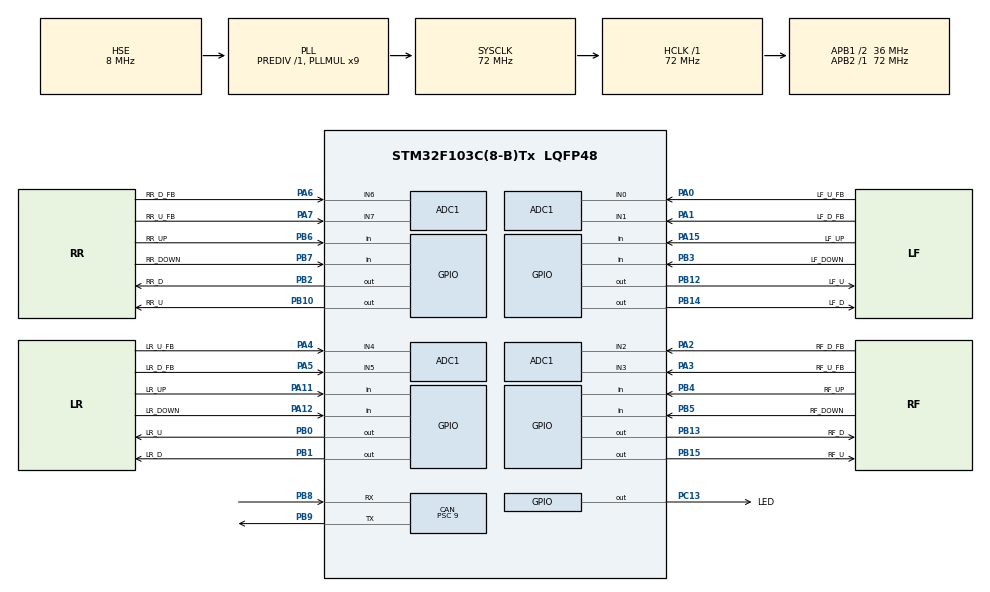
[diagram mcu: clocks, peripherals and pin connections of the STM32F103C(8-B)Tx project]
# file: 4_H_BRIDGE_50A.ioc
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Mcu.Family=STM32F1
PB10.GPIO_PuPd=GPIO_PULLDOWN
ADC1.ContinuousConvMode=ENABLE
SH.ADCx_IN2.0=ADC1_IN2,IN2
PB14.GPIO_Label=LF_D
PA6.GPIO_Label=RR_D_FB
PB0.GPIO_Label=LR_U
PB6.GPIO_Label=RR_UP
PA11.GPIO_PuPd=GPIO_PULLUP
PB13.GPIO_Label=RF_D
PB13.Signal=GPIO_Output
PB15.Signal=GPIO_Output
RCC.SYSCLKSource=RCC_SYSCLKSOURCE_PLLCLK
ProjectManager.StackSize=0x400
PD1-OSC_OUT.Signal=RCC_OSC_OUT
PA15.GPIO_Label=LF_UP
PA12.Signal=GPIO_Input
CAN.Prescaler=9
ADC1.Channel-3\#ChannelRegularConversion=ADC_CHANNEL_3
PB1.GPIO_PuPd=GPIO_PULLDOWN
RCC.HCLKFreq_Value=72000000
SH.ADCx_IN3.0=ADC1_IN3,IN3
RCC.APB2TimFreq_Value=72000000
PB6.Signal=GPIO_Input
Dma.ADC1.0.Direction=DMA_PERIPH_TO_MEMORY
ADC1.Channel-2\#ChannelRegularConversion=ADC_CHANNEL_2
Dma.ADC1.0.MemDataAlignment=DMA_MDATAALIGN_WORD
RCC.AHBFreq_Value=72000000
VP_TIM4_VS_ControllerModeTrigger.Mode=Trigger Mode
ADC1.Channel-0\#ChannelRegularConversion=ADC_CHANNEL_0
PB2.Signal=GPIO_Output
RCC.PLLMUL=RCC_PLL_MUL9
PB12.GPIO_Label=LF_U
PB3.GPIO_PuPd=GPIO_PULLUP
ADC1.Rank-2\#ChannelRegularConversion=3
PC14-OSC32_IN.Mode=LSE-External-Oscillator
PA14.Mode=Serial_Wire
PB1.GPIO_Label=LR_D
Dma.ADC1.0.PeriphInc=DMA_PINC_DISABLE
PB7.Signal=GPIO_Input
SH.ADCx_IN0.0=ADC1_IN0,IN0
TIM4.Period=200
CAN.CalculateTimeQuantum=250.0
PB2.GPIO_PuPd=GPIO_PULLDOWN
ADC1.SamplingTime-0\#ChannelRegularConversion=ADC_SAMPLETIME_1CYCLE_5
PB7.GPIO_Label=RR_DOWN
Mcu.Package=LQFP48
PB9.Signal=CAN_TX
PB14.GPIO_PuPd=GPIO_PULLDOWN
PB1.Signal=GPIO_Output
PA6.Signal=ADCx_IN6
ADC1.EnableInjectedConversion=DISABLE
PB15.GPIO_PuPd=GPIO_PULLDOWN
PA2.GPIO_Label=RF_D_FB
PA15.Signal=GPIO_Input
SH.ADCx_IN1.0=ADC1_IN1,IN1
PB5.GPIO_Label=RF_DOWN
RCC.APB1TimFreq_Value=72000000
PA12.GPIO_PuPd=GPIO_PULLUP
Dma.Request0=ADC1
PA4.GPIO_Label=LR_U_FB
PB4.Signal=GPIO_Input
PA3.Signal=ADCx_IN3
PB3.GPIO_Label=LF_DOWN
PB7.GPIO_PuPd=GPIO_PULLUP
RCC.PLLSourceVirtual=RCC_PLLSOURCE_HSE
PC15-OSC32_OUT.Mode=LSE-External-Oscillator
Dma.ADC1.0.Instance=DMA1_Channel1
ADC1.Rank-0\#ChannelRegularConversion=1
PD1-OSC_OUT.Mode=HSE-External-Oscillator
SH.ADCx_IN6.0=ADC1_IN6,IN6
CAN.CalculateBaudRate=500000
PB6.GPIO_PuPd=GPIO_PULLUP
PC13-TAMPER-RTC.Signal=GPIO_Output
PA11.GPIO_Label=LR_UP
PD0-OSC_IN.Signal=RCC_OSC_IN
RCC.APB1CLKDivider=RCC_HCLK_DIV2
PC14-OSC32_IN.Signal=RCC_OSC32_IN
CAN.CalculateTimeBit=2000.00
PA12.GPIO_Label=LR_DOWN
ADC1.SamplingTime-2\#ChannelRegularConversion=ADC_SAMPLETIME_13CYCLES_5
PA0-WKUP.GPIO_Label=LF_U_FB
PA0-WKUP.Signal=ADCx_IN0
RCC.ADCPresc=RCC_ADCPCLK2_DIV6
PA13.Signal=SYS_JTMS-SWDIO
Dma.ADC1.0.PeriphDataAlignment=DMA_PDATAALIGN_WORD
CAN.BS2=CAN_BS2_3TQ
CAN.BS1=CAN_BS1_4TQ
ProjectManager.TargetToolchain=Makefile
PB10.GPIO_Label=RR_U
SH.ADCx_IN7.0=ADC1_IN7,IN7
Dma.ADC1.0.Mode=DMA_CIRCULAR
PB9.Mode=CAN_Activate
Dma.ADC1.0.Priority=DMA_PRIORITY_MEDIUM
ADC1.Channel-1\#ChannelRegularConversion=ADC_CHANNEL_1
PB4.GPIO_PuPd=GPIO_PULLUP
RCC.USBFreq_Value=72000000
PC15-OSC32_OUT.Signal=RCC_OSC32_OUT
PA1.Signal=ADCx_IN1
PD0-OSC_IN.Mode=HSE-External-Oscillator
PB10.Signal=GPIO_Output
PB14.Signal=GPIO_Output
PA5.Signal=ADCx_IN5
board=custom
PC13-TAMPER-RTC.GPIO_Label=LED
PB13.GPIO_PuPd=GPIO_PULLDOWN
RCC.APB2Freq_Value=72000000
PB4.GPIO_Label=RF_UP
PB15.GPIO_Label=RF_U
VP_TIM4_VS_ClockSourceITR.Mode=TriggerSource_ITR0
NVIC.USB_LP_CAN1_RX0_IRQn=true\:0\:0\:false\:false\:true\:true\:true
PA1.GPIO_Label=LF_D_FB
SH.ADCx_IN4.0=ADC1_IN4,IN4
ADC1.NbrOfConversion=4
PA13.Mode=Serial_Wire
Mcu.Name=STM32F103C(8-B)Tx
PA2.Signal=ADCx_IN2
PB3.Signal=GPIO_Input
PA4.Signal=ADCx_IN4
ADC1.SamplingTime-1\#ChannelRegularConversion=ADC_SAMPLETIME_13CYCLES_5
RCC.SYSCLKFreq_VALUE=72000000
PB5.Signal=GPIO_Input
PA7.GPIO_Label=RR_U_FB
ADC1.master=1
PA5.GPIO_Label=LR_D_FB
ADC1.Rank-3\#ChannelRegularConversion=4
ADC1.SamplingTime-3\#ChannelRegularConversion=ADC_SAMPLETIME_13CYCLES_5
PB5.GPIO_PuPd=GPIO_PULLUP
ADC1.Rank-1\#ChannelRegularConversion=2
PA11.Signal=GPIO_Input
PA14.Signal=SYS_JTCK-SWCLK
Dma.ADC1.0.MemInc=DMA_MINC_ENABLE
PB2.GPIO_Label=RR_D
ProjectManager.HeapSize=0x200
SH.ADCx_IN5.0=ADC1_IN5,IN5
NVIC.PriorityGroup=NVIC_PRIORITYGROUP_4
ADC1.NbrOfConversionFlag=1
PB8.Mode=CAN_Activate
PA15.GPIO_PuPd=GPIO_PULLUP
PB8.Signal=CAN_RX
NVIC.DMA1_Channel1_IRQn=true\:0\:0\:false\:false\:true\:false\:true
PB12.GPIO_PuPd=GPIO_PULLDOWN
NVIC.TIM4_IRQn=true\:0\:0\:false\:false\:true\:true\:true
RCC.APB1Freq_Value=36000000
PB0.Signal=GPIO_Output
PB12.Signal=GPIO_Output
PB0.GPIO_PuPd=GPIO_PULLDOWN
PA3.GPIO_Label=RF_U_FB
PA7.Signal=ADCx_IN7

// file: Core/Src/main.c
/* USER CODE BEGIN Header */
/**
  ******************************************************************************
  * @file           : main.c
  * @brief          : Main program body
  ******************************************************************************
  * @attention
  *
  * <h2><center>&copy; Copyright (c) 2021 STMicroelectronics.
  * All rights reserved.</center></h2>
  *
  * This software component is licensed by ST under BSD 3-Clause license,
  * the "License"; You may not use this file except in compliance with the
  * License. You may obtain a copy of the License at:
  *                        opensource.org/licenses/BSD-3-Clause
  *
  ******************************************************************************
  */
/* USER CODE END Header */
#include "main.h"

/* USER CODE BEGIN Includes */
#include "window.h"
#include "can_setup.h"
/* USER CODE END Includes */

ADC_HandleTypeDef hadc1;
DMA_HandleTypeDef hdma_adc1;

CAN_HandleTypeDef hcan;

TIM_HandleTypeDef htim4;

void SystemClock_Config(void);
static void MX_GPIO_Init(void);
static void MX_DMA_Init(void);
static void MX_ADC1_Init(void);
static void MX_CAN_Init(void);
static void MX_TIM4_Init(void);

int main(void)
{

  /* MCU Configuration--------------------------------------------------------*/

  /* Reset of all peripherals, Initializes the Flash interface and the Systick. */
  HAL_Init();

  /* Configure the system clock */
  SystemClock_Config();

  /* Initialize all configured peripherals */
  MX_GPIO_Init();
  MX_DMA_Init();
  MX_ADC1_Init();
  MX_CAN_Init();
  MX_TIM4_Init();
  /* USER CODE BEGIN 2 */
  canSettings();
  windowInit();
  HAL_ADC_Start_DMA(&hadc1, motorCurrent, 8); // start adc in DMA mode
  /* USER CODE END 2 */

  /* Infinite loop */
  /* USER CODE BEGIN WHILE */
  while (1)
  {
    windowHandler();

    /* USER CODE END WHILE */

  }
}

void SystemClock_Config(void)
{
  RCC_OscInitTypeDef RCC_OscInitStruct = {0};
  RCC_ClkInitTypeDef RCC_ClkInitStruct = {0};
  RCC_PeriphCLKInitTypeDef PeriphClkInit = {0};

  /** Initializes the RCC Oscillators according to the specified parameters
  * in the RCC_OscInitTypeDef structure.
  */
  RCC_OscInitStruct.OscillatorType = RCC_OSCILLATORTYPE_HSE;
  RCC_OscInitStruct.HSEState = RCC_HSE_ON;
  RCC_OscInitStruct.HSEPredivValue = RCC_HSE_PREDIV_DIV1;
  RCC_OscInitStruct.HSIState = RCC_HSI_ON;
  RCC_OscInitStruct.PLL.PLLState = RCC_PLL_ON;
  RCC_OscInitStruct.PLL.PLLSource = RCC_PLLSOURCE_HSE;
  RCC_OscInitStruct.PLL.PLLMUL = RCC_PLL_MUL9;
  if (HAL_RCC_OscConfig(&RCC_OscInitStruct) != HAL_OK)
  {
    Error_Handler();
  }
  /** Initializes the CPU, AHB and APB buses clocks
  */
  RCC_ClkInitStruct.ClockType = RCC_CLOCKTYPE_HCLK | RCC_CLOCKTYPE_SYSCLK | RCC_CLOCKTYPE_PCLK1 | RCC_CLOCKTYPE_PCLK2;
  RCC_ClkInitStruct.SYSCLKSource = RCC_SYSCLKSOURCE_PLLCLK;
  RCC_ClkInitStruct.AHBCLKDivider = RCC_SYSCLK_DIV1;
  RCC_ClkInitStruct.APB1CLKDivider = RCC_HCLK_DIV2;
  RCC_ClkInitStruct.APB2CLKDivider = RCC_HCLK_DIV1;

  if (HAL_RCC_ClockConfig(&RCC_ClkInitStruct, FLASH_LATENCY_2) != HAL_OK)
  {
    Error_Handler();
  }
  PeriphClkInit.PeriphClockSelection = RCC_PERIPHCLK_ADC;
  PeriphClkInit.AdcClockSelection = RCC_ADCPCLK2_DIV6;
  if (HAL_RCCEx_PeriphCLKConfig(&PeriphClkInit) != HAL_OK)
  {
    Error_Handler();
  }
}

static void MX_ADC1_Init(void)
{

  ADC_ChannelConfTypeDef sConfig = {0};

  /** Common config
  */
  hadc1.Instance = ADC1;
  hadc1.Init.ScanConvMode = ADC_SCAN_ENABLE;
  hadc1.Init.ContinuousConvMode = ENABLE;
  hadc1.Init.DiscontinuousConvMode = DISABLE;
  hadc1.Init.ExternalTrigConv = ADC_SOFTWARE_START;
  hadc1.Init.DataAlign = ADC_DATAALIGN_RIGHT;
  hadc1.Init.NbrOfConversion = 8;
  if (HAL_ADC_Init(&hadc1) != HAL_OK)
  {
    Error_Handler();
  }
  /** Configure Regular Channel
  */
  sConfig.Channel = ADC_CHANNEL_0;
  sConfig.Rank = ADC_REGULAR_RANK_1;
  sConfig.SamplingTime = ADC_SAMPLETIME_1CYCLE_5;
  if (HAL_ADC_ConfigChannel(&hadc1, &sConfig) != HAL_OK)
  {
    Error_Handler();
  }
  /** Configure Regular Channel
  */
  sConfig.Channel = ADC_CHANNEL_1;
  sConfig.Rank = ADC_REGULAR_RANK_2;
  sConfig.SamplingTime = ADC_SAMPLETIME_1CYCLE_5;
  if (HAL_ADC_ConfigChannel(&hadc1, &sConfig) != HAL_OK)
  {
    Error_Handler();
  }
  /** Configure Regular Channel
  */
  sConfig.Channel = ADC_CHANNEL_2;
  sConfig.Rank = ADC_REGULAR_RANK_3;
  sConfig.SamplingTime = ADC_SAMPLETIME_1CYCLE_5;
  if (HAL_ADC_ConfigChannel(&hadc1, &sConfig) != HAL_OK)
  {
    Error_Handler();
  }
  /** Configure Regular Channel
  */
  sConfig.Channel = ADC_CHANNEL_3;
  sConfig.Rank = ADC_REGULAR_RANK_4;
  sConfig.SamplingTime = ADC_SAMPLETIME_1CYCLE_5;
  if (HAL_ADC_ConfigChannel(&hadc1, &sConfig) != HAL_OK)
  {
    Error_Handler();
  }
  /** Configure Regular Channel
  */
  sConfig.Channel = ADC_CHANNEL_4;
  sConfig.Rank = ADC_REGULAR_RANK_5;
  sConfig.SamplingTime = ADC_SAMPLETIME_1CYCLE_5;
  if (HAL_ADC_ConfigChannel(&hadc1, &sConfig) != HAL_OK)
  {
    Error_Handler();
  }
  /** Configure Regular Channel
  */
  sConfig.Channel = ADC_CHANNEL_5;
  sConfig.Rank = ADC_REGULAR_RANK_6;
  sConfig.SamplingTime = ADC_SAMPLETIME_1CYCLE_5;
  if (HAL_ADC_ConfigChannel(&hadc1, &sConfig) != HAL_OK)
  {
    Error_Handler();
  }
  /** Configure Regular Channel
  */
  sConfig.Channel = ADC_CHANNEL_6;
  sConfig.Rank = ADC_REGULAR_RANK_7;
  sConfig.SamplingTime = ADC_SAMPLETIME_1CYCLE_5;
  if (HAL_ADC_ConfigChannel(&hadc1, &sConfig) != HAL_OK)
  {
    Error_Handler();
  }
  /** Configure Regular Channel
  */
  sConfig.Channel = ADC_CHANNEL_7;
  sConfig.Rank = ADC_REGULAR_RANK_8;
  sConfig.SamplingTime = ADC_SAMPLETIME_1CYCLE_5;
  if (HAL_ADC_ConfigChannel(&hadc1, &sConfig) != HAL_OK)
  {
    Error_Handler();
  }
}

static void MX_CAN_Init(void)
{

  hcan.Instance = CAN1;
  hcan.Init.Prescaler = 9;
  hcan.Init.Mode = CAN_MODE_NORMAL;
  hcan.Init.SyncJumpWidth = CAN_SJW_1TQ;
  hcan.Init.TimeSeg1 = CAN_BS1_4TQ;
  hcan.Init.TimeSeg2 = CAN_BS2_3TQ;
  hcan.Init.TimeTriggeredMode = DISABLE;
  hcan.Init.AutoBusOff = DISABLE;
  hcan.Init.AutoWakeUp = DISABLE;
  hcan.Init.AutoRetransmission = DISABLE;
  hcan.Init.ReceiveFifoLocked = DISABLE;
  hcan.Init.TransmitFifoPriority = DISABLE;
  if (HAL_CAN_Init(&hcan) != HAL_OK)
  {
    Error_Handler();
  }
}

static void MX_TIM4_Init(void)
{

  TIM_SlaveConfigTypeDef sSlaveConfig = {0};
  TIM_MasterConfigTypeDef sMasterConfig = {0};

  htim4.Instance = TIM4;
  htim4.Init.Prescaler = 0;
  htim4.Init.CounterMode = TIM_COUNTERMODE_UP;
  htim4.Init.Period = 200;
  htim4.Init.ClockDivision = TIM_CLOCKDIVISION_DIV1;
  htim4.Init.AutoReloadPreload = TIM_AUTORELOAD_PRELOAD_DISABLE;
  if (HAL_TIM_Base_Init(&htim4) != HAL_OK)
  {
    Error_Handler();
  }
  sSlaveConfig.SlaveMode = TIM_SLAVEMODE_TRIGGER;
  sSlaveConfig.InputTrigger = TIM_TS_ITR0;
  if (HAL_TIM_SlaveConfigSynchro(&htim4, &sSlaveConfig) != HAL_OK)
  {
    Error_Handler();
  }
  sMasterConfig.MasterOutputTrigger = TIM_TRGO_RESET;
  sMasterConfig.MasterSlaveMode = TIM_MASTERSLAVEMODE_DISABLE;
  if (HAL_TIMEx_MasterConfigSynchronization(&htim4, &sMasterConfig) != HAL_OK)
  {
    Error_Handler();
  }
}

static void MX_DMA_Init(void)
{

  /* DMA controller clock enable */
  __HAL_RCC_DMA1_CLK_ENABLE();

  /* DMA interrupt init */
  /* DMA1_Channel1_IRQn interrupt configuration */
  HAL_NVIC_SetPriority(DMA1_Channel1_IRQn, 0, 0);
  HAL_NVIC_EnableIRQ(DMA1_Channel1_IRQn);
}

static void MX_GPIO_Init(void)
{
  GPIO_InitTypeDef GPIO_InitStruct = {0};

  /* GPIO Ports Clock Enable */
  __HAL_RCC_GPIOC_CLK_ENABLE();
  __HAL_RCC_GPIOD_CLK_ENABLE();
  __HAL_RCC_GPIOA_CLK_ENABLE();
  __HAL_RCC_GPIOB_CLK_ENABLE();

  /*Configure GPIO pin Output Level */
  HAL_GPIO_WritePin(LED_GPIO_Port, LED_Pin, GPIO_PIN_RESET);

  /*Configure GPIO pin Output Level */
  HAL_GPIO_WritePin(GPIOB, LR_U_Pin | LR_D_Pin | RR_D_Pin | RR_U_Pin | LF_U_Pin | RF_D_Pin | LF_D_Pin | RF_U_Pin, GPIO_PIN_RESET);

  /*Configure GPIO pin : LED_Pin */
  GPIO_InitStruct.Pin = LED_Pin;
  GPIO_InitStruct.Mode = GPIO_MODE_OUTPUT_PP;
  GPIO_InitStruct.Pull = GPIO_NOPULL;
  GPIO_InitStruct.Speed = GPIO_SPEED_FREQ_LOW;
  HAL_GPIO_Init(LED_GPIO_Port, &GPIO_InitStruct);

  /*Configure GPIO pins : LR_U_Pin LR_D_Pin RR_D_Pin RR_U_Pin
                           LF_U_Pin RF_D_Pin LF_D_Pin RF_U_Pin */
  GPIO_InitStruct.Pin = LR_U_Pin | LR_D_Pin | RR_D_Pin | RR_U_Pin | LF_U_Pin | RF_D_Pin | LF_D_Pin | RF_U_Pin;
  GPIO_InitStruct.Mode = GPIO_MODE_OUTPUT_PP;
  GPIO_InitStruct.Pull = GPIO_PULLDOWN;
  GPIO_InitStruct.Speed = GPIO_SPEED_FREQ_LOW;
  HAL_GPIO_Init(GPIOB, &GPIO_InitStruct);

  /*Configure GPIO pins : LR_UP_Pin LR_DOWN_Pin LF_UP_Pin */
  GPIO_InitStruct.Pin = LR_UP_Pin | LR_DOWN_Pin | LF_UP_Pin;
  GPIO_InitStruct.Mode = GPIO_MODE_INPUT;
  GPIO_InitStruct.Pull = GPIO_PULLUP;
  HAL_GPIO_Init(GPIOA, &GPIO_InitStruct);

  /*Configure GPIO pins : LF_DOWN_Pin RF_UP_Pin RF_DOWN_Pin RR_UP_Pin
                           RR_DOWN_Pin */
  GPIO_InitStruct.Pin = LF_DOWN_Pin | RF_UP_Pin | RF_DOWN_Pin | RR_UP_Pin | RR_DOWN_Pin;
  GPIO_InitStruct.Mode = GPIO_MODE_INPUT;
  GPIO_InitStruct.Pull = GPIO_PULLUP; // test pulldown
  HAL_GPIO_Init(GPIOB, &GPIO_InitStruct);
}

void Error_Handler(void)
{
  __disable_irq();
  while (1)
  {
  }
}

/************************ (C) COPYRIGHT STMicroelectronics *****END OF FILE****/
